# I2CS register map
Vendor: Texas Instruments
Peripheral module from a debugger description file (folder cc2538).
Registers are 32-bit, access per field, no defined reset value unless marked. A register's access mark holds for its fields unless they carry their own. Offsets are as the file gives them; lines under a group give offsets from that group; [hi:lo] are bit positions; {n}, {i} and the like mark numbered series; 'fields as' and 'values as' point back to an identical list; <NAME> marks a mode.

## I2CS — Register fields should be considered static unless otherwise noted as dynamic.
0x00 OAR — I2C slave own address This register consists of seven address bits that identify the CC2538 I2C device on the I2C bus.
  [6:0] OAR rw — I2C slave own address This field specifies bits A6 through A0 of the slave address.
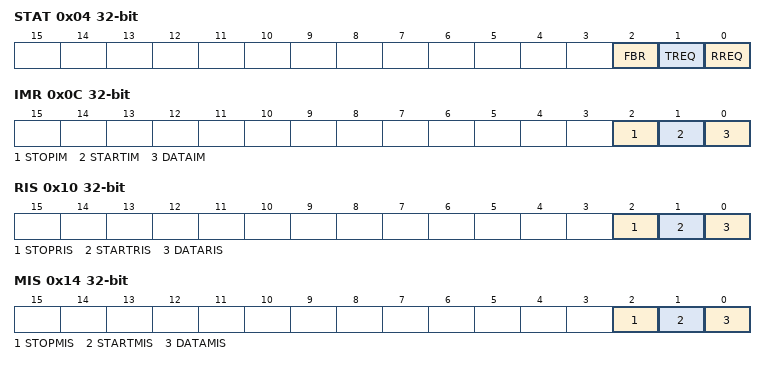
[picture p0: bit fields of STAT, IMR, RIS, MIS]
0x04 STAT ro — I2C slave control and status This register functions as a control register when written, and a status register when read.
  [2] FBR — First byte received 1: The first byte following the slave's own address has been received. 0: The first byte has not been received. This bit is only valid when the RREQ bit is set and is automatically cleared when data has been read from the I2CSDR register. Note: This bit is not used for slave transmit operations.
  [1] TREQ — Transmit request 1: The I2C controller has been addressed as a slave transmitter and is using clock stretching to delay the master until data has been written to the I2CSDR register. 0: No outstanding transmit request.
  [0] RREQ — Receive request 1: The I2C controller has outstanding receive data from the I2C master and is using clock stretching to delay the master until data has been read from the I2CSDR register. 0: No outstanding receive data
0x04 CTRL wo — I2C slave control and status This register functions as a control register when written, and a status register when read.
  [0] DA — Device active 0: Disables the I2C slave operation 1: Enables the I2C slave operation
0x08 DR — I2C slave data This register contains the data to be transmitted when in the slave transmit state, and the data received when in the slave receive state.
  [7:0] DATA rw — Data for transfer This field contains the data for transfer during a slave receive or transmit operation.
0x0C IMR — I2C slave interrupt mask This register controls whether a raw interrupt is promoted to a controller interrupt.
  [2] STOPIM ro — Stop condition interrupt mask 1: The STOP condition interrupt is sent to the interrupt controller when the STOPRIS bit in the I2CSRIS register is set. 0: The STOPRIS interrupt is supressed and not sent to the interrupt controller.
  [1] STARTIM ro — Start condition interrupt mask 1: The START condition interrupt is sent to the interrupt controller when the STARTRIS bit in the I2CSRIS register is set. 0: The STARTRIS interrupt is supressed and not sent to the interrupt controller.
  [0] DATAIM rw — Data interrupt mask 1: The data received or data requested interrupt is sent to the interrupt controller when the DATARIS bit in the I2CSRIS register is set. 0: The DATARIS interrupt is surpressed and not sent to the interrupt controller.
0x10 RIS ro — I2C slave raw interrupt status This register specifies whether an interrupt is pending.
  [2] STOPRIS — Stop condition raw interrupt status 1: A STOP condition interrupt is pending. 0: No interrupt This bit is cleared by writing 1 to the STOPIC bit in the I2CSICR register.
  [1] STARTRIS — Start condition raw interrupt status 1: A START condition interrupt is pending. 0: No interrupt This bit is cleared by writing 1 to the STARTIC bit in the I2CSICR register.
  [0] DATARIS — Data raw interrupt status 1: A data received or data requested interrupt is pending. 0: No interrupt This bit is cleared by writing 1 to the DATAIC bit in the I2CSICR register.
0x14 MIS ro — I2C slave masked interrupt status This register specifies whether an interrupt was signaled.
  [2] STOPMIS — Stop condition masked interrupt status 1: An unmasked STOP condition interrupt is pending. 0: An interrupt has not occurred or is masked. This bit is cleared by writing 1 to the STOPIC bit in the I2CSICR register.
  [1] STARTMIS — Start condition masked interrupt status 1: An unmasked START condition interrupt is pending. 0: An interrupt has not occurred or is masked. This bit is cleared by writing 1 to the STARTIC bit in the I2CSICR register.
  [0] DATAMIS — Data masked interrupt status 1: An unmasked data received or data requested interrupt is pending. 0: An interrupt has not occurred or is masked. This bit is cleared by writing 1 to the DATAIC bit in the I2CSICR register.
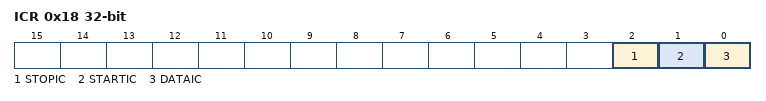
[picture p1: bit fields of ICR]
0x18 ICR wo — I2C slave interrupt clear This register clears the raw interrupt. A read of this register returns no meaningful data.
  [2] STOPIC — Stop condition interrupt clear Writing 1 to this bit clears the STOPRIS bit in the I2CSRIS register and the STOPMIS bit in the I2CSMIS register. A read of this register returns no meaningful data.
  [1] STARTIC — Start condition interrupt vlear Writing 1 to this bit clears the STARTRIS bit in the I2CSRIS register and the STARTMIS bit in the I2CSMIS register. A read of this register returns no meaningful data.
  [0] DATAIC — Data interrupt clear Writing 1 to this bit clears the DATARIS bit in the I2CSRIS register and the DATAMIS bit in the I2CSMIS register. A read of this register returns no meaningful data.
